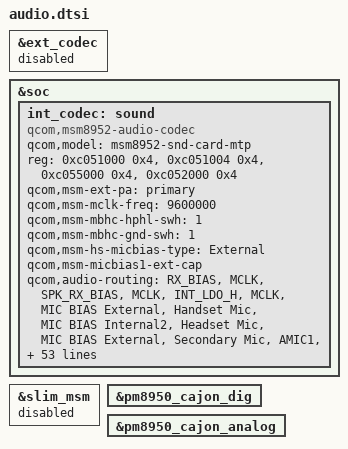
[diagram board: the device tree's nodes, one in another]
/*
 * Copyright (c) 2015, The Linux Foundation. All rights reserved.
 *
 * This program is free software; you can redistribute it and/or modify
 * it under the terms of the GNU General Public License version 2 and
 * only version 2 as published by the Free Software Foundation.
 *
 * This program is distributed in the hope that it will be useful,
 * but WITHOUT ANY WARRANTY; without even the implied warranty of
 * MERCHANTABILITY or FITNESS FOR A PARTICULAR PURPOSE.  See the
 * GNU General Public License for more details.
 */



&ext_codec {
	status = "disabled";
};
/*&&tlmm_pinmux{
    aw87319_rst{
    qcom,pins = <&gp 18>, <&gp 19>;
    qcom,num-grp-pins = <2>;
    label = "aw87319_rst";
    qcom,pin-func = <3>;
    aw87319_rst_high:rst_high{
       drive-strength = <2>;
       bias-pull-up;
         };
    aw87319_rst_low:rst_low{
       drive-strength = <2>;
       bias-pull-up;
         };
    };
};
*/
&soc {
int_codec:sound {
		compatible = "qcom,msm8952-audio-codec";
		qcom,model = "msm8952-snd-card-mtp";
		reg = <0xc051000 0x4>,
		    <0xc051004 0x4>,
		    <0xc055000 0x4>,
		    <0xc052000 0x4>;
		reg-names = "csr_gp_io_mux_mic_ctl",
			"csr_gp_io_mux_spkr_ctl",
			"csr_gp_io_lpaif_pri_pcm_pri_mode_muxsel",
			"csr_gp_io_mux_quin_ctl";

		qcom,msm-ext-pa = "primary";
		qcom,msm-mclk-freq = <9600000>;
		qcom,msm-mbhc-hphl-swh = <1>;
		qcom,msm-mbhc-gnd-swh = <1>;
		qcom,msm-hs-micbias-type = "External";
		qcom,msm-micbias1-ext-cap;
		qcom,audio-routing =
			"RX_BIAS", "MCLK",
			"SPK_RX_BIAS", "MCLK",
			"INT_LDO_H", "MCLK",
			"MIC BIAS External", "Handset Mic",
			"MIC BIAS Internal2", "Headset Mic",
			"MIC BIAS External", "Secondary Mic",
			"AMIC1", "MIC BIAS External",
			"AMIC2", "MIC BIAS Internal2",
			"AMIC3", "MIC BIAS External",
			"WSA_SPK OUT", "VDD_WSA_SWITCH",
			"SpkrMono WSA_IN", "WSA_SPK OUT";
		qcom,msm-gpios =
			"pri_i2s";
		qcom,pinctrl-names =
			"all_off",
			"pri_i2s_act";
		pinctrl-names =
			"all_off",
			"pri_i2s_act";
		pinctrl-0 = <&cdc_pdm_lines_sus &cdc_pdm_lines_2_sus>;
		pinctrl-1 = <&cdc_pdm_lines_act &cdc_pdm_lines_2_act>;
/*		pinctrl-2 = <&cdc_pdm_lines_sus &cdc_pdm_lines_2_sus>;
		pinctrl-3 = <&cdc_pdm_lines_act &cdc_pdm_lines_2_act>;*/
		qcom,swap-en0-gpios = <&pm8950_gpios 6 0x00>;
		qcom,swap-en1-gpios = <&pm8950_gpios 7 0x00>;
		asoc-platform = <&pcm0>, <&pcm1>, <&pcm2>, <&voip>, <&voice>,
			<&loopback>, <&compress>, <&hostless>,
			<&afe>, <&lsm>, <&routing>, <&lpa>,
			<&voice_svc>;
		asoc-platform-names = "msm-pcm-dsp.0", "msm-pcm-dsp.1",
			"msm-pcm-dsp.2", "msm-voip-dsp",
			"msm-pcm-voice", "msm-pcm-loopback",
			"msm-compress-dsp", "msm-pcm-hostless",
			"msm-pcm-afe", "msm-lsm-client",
			"msm-pcm-routing", "msm-pcm-lpa",
			"msm-voice-svc";
		asoc-cpu = <&dai_pri_auxpcm>, <&dai_hdmi>,
			<&dai_mi2s0>, <&dai_mi2s1>, <&dai_mi2s2>,
			<&dai_mi2s3>, <&dai_mi2s5>, <&dai_mi2s6>,
			<&sb_0_rx>, <&sb_0_tx>, <&sb_1_rx>, <&sb_1_tx>,
			<&sb_3_rx>, <&sb_3_tx>, <&sb_4_rx>, <&sb_4_tx>,
			<&bt_sco_rx>, <&bt_sco_tx>, <&int_fm_rx>,
			<&int_fm_tx>, <&afe_pcm_rx>, <&afe_pcm_tx>,
			<&afe_proxy_rx>, <&afe_proxy_tx>,
			<&incall_record_rx>, <&incall_record_tx>,
			<&incall_music_rx>, <&incall_music_2_rx>;
		asoc-cpu-names = "msm-dai-q6-auxpcm.1", "msm-dai-q6-hdmi.8",
			"msm-dai-q6-mi2s.0", "msm-dai-q6-mi2s.1",
			"msm-dai-q6-mi2s.2", "msm-dai-q6-mi2s.3",
			"msm-dai-q6-mi2s.5", "msm-dai-q6-mi2s.6",
			"msm-dai-q6-dev.16384", "msm-dai-q6-dev.16385",
			"msm-dai-q6-dev.16386", "msm-dai-q6-dev.16387",
			"msm-dai-q6-dev.16390", "msm-dai-q6-dev.16391",
			"msm-dai-q6-dev.16392", "msm-dai-q6-dev.16393",
			"msm-dai-q6-dev.12288", "msm-dai-q6-dev.12289",
			"msm-dai-q6-dev.12292", "msm-dai-q6-dev.12293",
			"msm-dai-q6-dev.224", "msm-dai-q6-dev.225",
			"msm-dai-q6-dev.241", "msm-dai-q6-dev.240",
			"msm-dai-q6-dev.32771", "msm-dai-q6-dev.32772",
			"msm-dai-q6-dev.32773", "msm-dai-q6-dev.32770";
		asoc-codec = <&stub_codec>, <&pm8950_cajon_dig>;
		asoc-codec-names = "msm-stub-codec.1", "cajon_codec";
		asoc-wsa-codec-names;
		asoc-wsa-codec-prefixes = "SpkrMono";

		msm-vdd-wsa-switch-supply = <&pm8950_l13>;
		qcom,msm-vdd-wsa-switch-voltage = <3075000>;
		qcom,msm-vdd-wsa-switch-current = <5000>;
	};
};

&slim_msm{
	status = "disabled";
};

&pm8950_cajon_dig {
	status = "ok";
};

&pm8950_cajon_analog {
	status = "ok";
};

